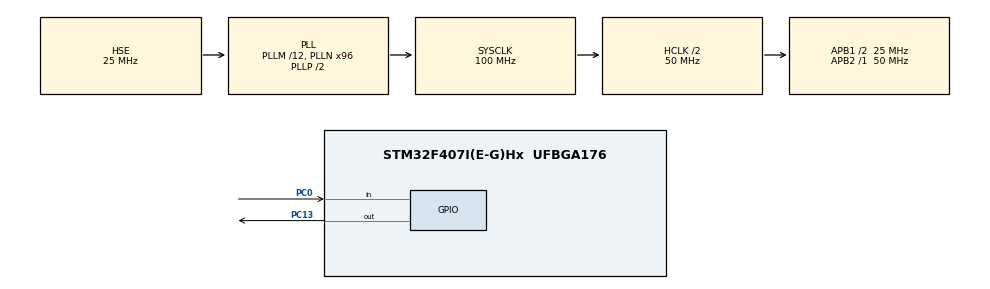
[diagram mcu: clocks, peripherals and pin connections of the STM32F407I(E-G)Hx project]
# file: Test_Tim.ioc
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Mcu.Family=STM32F4
Mcu.Name=STM32F407I(E-G)Hx
Mcu.Package=UFBGA176
NVIC.PriorityGroup=NVIC_PRIORITYGROUP_4
NVIC.TIM3_IRQn=true\:0\:0\:false\:false\:true\:true\:true\:true
PA0-WKUP.Mode=SYS_WakeUp0
PA0-WKUP.Signal=SYS_WKUP
PA13.Mode=Serial_Wire
PA13.Signal=SYS_JTMS-SWDIO
PA14.Mode=Serial_Wire
PA14.Signal=SYS_JTCK-SWCLK
PC0.GPIO_PuPd=GPIO_PULLUP
PC0.Signal=GPIO_Input
PC13-ANTI_TAMP.PinState=GPIO_PIN_SET
PC13-ANTI_TAMP.Signal=GPIO_Output
PH0-OSC_IN.Mode=HSE-External-Oscillator
PH0-OSC_IN.Signal=RCC_OSC_IN
PH1-OSC_OUT.Mode=HSE-External-Oscillator
PH1-OSC_OUT.Signal=RCC_OSC_OUT
ProjectManager.HeapSize=0x200
ProjectManager.StackSize=0x400
ProjectManager.TargetToolchain=MDK-ARM V5.32
RCC.48MHZClocksFreq_Value=50000000
RCC.AHBCLKDivider=RCC_SYSCLK_DIV2
RCC.AHBFreq_Value=50000000
RCC.APB1CLKDivider=RCC_HCLK_DIV2
RCC.APB1Freq_Value=25000000
RCC.APB1TimFreq_Value=50000000
RCC.APB2Freq_Value=50000000
RCC.APB2TimFreq_Value=50000000
RCC.CortexFreq_Value=50000000
RCC.HCLKFreq_Value=50000000
RCC.HSE_VALUE=25000000
RCC.HSI_VALUE=16000000
RCC.LSE_VALUE=32768
RCC.PLLM=12
RCC.PLLN=96
RCC.PLLSourceVirtual=RCC_PLLSOURCE_HSE
RCC.SYSCLKFreq_VALUE=100000000
RCC.SYSCLKSource=RCC_SYSCLKSOURCE_PLLCLK
RCC.VCOOutputFreq_Value=200000000
TIM3.Period=49999
TIM3.Prescaler=999
VP_TIM3_VS_ClockSourceINT.Mode=Internal
board=custom

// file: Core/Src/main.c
/* USER CODE BEGIN Header */
/**
  ******************************************************************************
  * @file           : main.c
  * @brief          : Main program body
  ******************************************************************************
  * @attention
  *
  * Copyright (c) 2025 STMicroelectronics.
  * All rights reserved.
  *
  * This software is licensed under terms that can be found in the LICENSE file
  * in the root directory of this software component.
  * If no LICENSE file comes with this software, it is provided AS-IS.
  *
  ******************************************************************************
  */
/* USER CODE END Header */
#include "main.h"
#include "tim.h"
#include "gpio.h"

/* USER CODE BEGIN PV */
GPIO_PinState PinState;
GPIO_PinState last_PinState;
/* USER CODE END PV */

void SystemClock_Config(void);

int main(void)
{

  /* MCU Configuration--------------------------------------------------------*/

  /* Reset of all peripherals, Initializes the Flash interface and the Systick. */
  HAL_Init();

  /* Configure the system clock */
  SystemClock_Config();

  /* Initialize all configured peripherals */
  MX_GPIO_Init();
  MX_TIM3_Init();
  /* USER CODE BEGIN 2 */
	HAL_TIM_Base_Init(&htim3);
  /* USER CODE END 2 */

  /* Infinite loop */
  while (1)
  {

  }
}

void SystemClock_Config(void)
{
  RCC_OscInitTypeDef RCC_OscInitStruct = {0};
  RCC_ClkInitTypeDef RCC_ClkInitStruct = {0};

  /** Configure the main internal regulator output voltage
  */
  __HAL_RCC_PWR_CLK_ENABLE();
  __HAL_PWR_VOLTAGESCALING_CONFIG(PWR_REGULATOR_VOLTAGE_SCALE1);

  /** Initializes the RCC Oscillators according to the specified parameters
  * in the RCC_OscInitTypeDef structure.
  */
  RCC_OscInitStruct.OscillatorType = RCC_OSCILLATORTYPE_HSE;
  RCC_OscInitStruct.HSEState = RCC_HSE_ON;
  RCC_OscInitStruct.PLL.PLLState = RCC_PLL_ON;
  RCC_OscInitStruct.PLL.PLLSource = RCC_PLLSOURCE_HSE;
  RCC_OscInitStruct.PLL.PLLM = 12;
  RCC_OscInitStruct.PLL.PLLN = 96;
  RCC_OscInitStruct.PLL.PLLP = RCC_PLLP_DIV2;
  RCC_OscInitStruct.PLL.PLLQ = 4;
  if (HAL_RCC_OscConfig(&RCC_OscInitStruct) != HAL_OK)
  {
    Error_Handler();
  }

  /** Initializes the CPU, AHB and APB buses clocks
  */
  RCC_ClkInitStruct.ClockType = RCC_CLOCKTYPE_HCLK|RCC_CLOCKTYPE_SYSCLK
                              |RCC_CLOCKTYPE_PCLK1|RCC_CLOCKTYPE_PCLK2;
  RCC_ClkInitStruct.SYSCLKSource = RCC_SYSCLKSOURCE_PLLCLK;
  RCC_ClkInitStruct.AHBCLKDivider = RCC_SYSCLK_DIV2;
  RCC_ClkInitStruct.APB1CLKDivider = RCC_HCLK_DIV2;
  RCC_ClkInitStruct.APB2CLKDivider = RCC_HCLK_DIV1;

  if (HAL_RCC_ClockConfig(&RCC_ClkInitStruct, FLASH_LATENCY_1) != HAL_OK)
  {
    Error_Handler();
  }
}

/* USER CODE BEGIN 4 */
void HAL_TIM_PeriodElapsedCallback(TIM_HandleTypeDef *htim)
{
	if(htim == &htim3)
  {PinState = HAL_GPIO_ReadPin(GPIOC,GPIO_PIN_0);
  last_PinState = PinState;
	}//详解见视频,还有就是怎么把我main函数的代码给吞了www
}
/* USER CODE END 4 */

void Error_Handler(void)
{
  __disable_irq();
  while (1)
  {
  }
}
